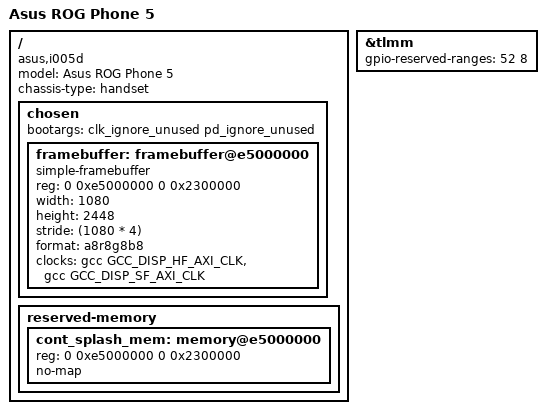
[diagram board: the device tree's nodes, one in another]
// SPDX-License-Identifier: GPL-2.0-only

/dts-v1/;

#include "sm8350.dtsi"

/ {
	model = "Asus ROG Phone 5";
	compatible = "asus,i005d", "qcom,sm8350";
	chassis-type = "handset";

	chosen {
		#address-cells = <2>;
		#size-cells = <2>;
		ranges;

		bootargs = "clk_ignore_unused pd_ignore_unused";

		framebuffer: framebuffer@e5000000 {
			compatible = "simple-framebuffer";
			reg = <0 0xe5000000 0 0x2300000>;

			width = <1080>;
			height = <2448>;
			stride = <(1080 * 4)>;
			format = "a8r8g8b8";
			/*
			 * That's (going to be) a lot of clocks, but it's necessary due
			 * to unused clk cleanup & no panel driver yet
			 */
			clocks = <&gcc GCC_DISP_HF_AXI_CLK>,
					<&gcc GCC_DISP_SF_AXI_CLK>;
		};
	};

	reserved-memory {
		cont_splash_mem: memory@e5000000 {
			reg = <0 0xe5000000 0 0x2300000>;
			no-map;
		};
	};
};

&tlmm {
	gpio-reserved-ranges = <52 8>;
};
